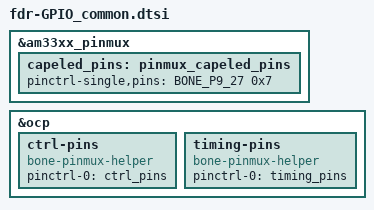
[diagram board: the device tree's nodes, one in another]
#include <dt-bindings/board/am335x-bbw-bbb-base.h>
#include <dt-bindings/pinctrl/am33xx.h>



&am33xx_pinmux {

    capeled_pins: pinmux_capeled_pins {
            pinctrl-single,pins = <
            BONE_P9_27 0x7   /* gpio3_19 Cape led */
            >;
    };
};


&ocp {
		ctrl-pins {
			compatible = "bone-pinmux-helper";
			pinctrl-names = "default";
			pinctrl-0 = <&ctrl_pins>;
			status = "okay";
		};

		timing-pins {
			compatible = "bone-pinmux-helper";
			pinctrl-names = "default";
			pinctrl-0 = <&timing_pins>;
			status = "okay";
		};
};
